# NUC400_v1 register map
File version: 1.0
Registers are 32-bit, read-write, reset 0x0 unless marked. A register's access mark holds for its fields unless they carry their own. Offsets are from the block's base; [hi:lo] are bit positions; {n}, {i} and the like mark numbered series.

## ACMP — ACMP Register Map
Base 0x40045000
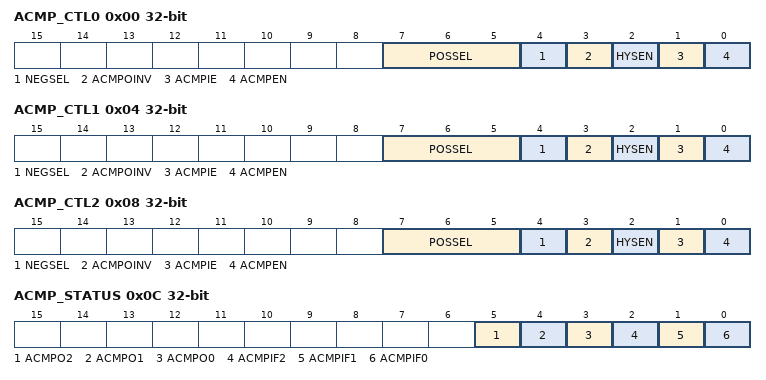
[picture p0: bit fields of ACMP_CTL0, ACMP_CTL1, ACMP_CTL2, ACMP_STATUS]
0x00 ACMP_CTL0 — Analog Comparator 0 Control Register
  [7:5] POSSEL — Comparator 0 Positive Input Selection. The other options are reserved.
    {v}=Input from ACMP0_P{v} (v=0..3); 4=Input from OPA0
  [4] NEGSEL — Comparator 0 Negative Input Selection
    0=The source of comparator 0 negative input is from ACMP0_N pin; 1=The internal comparator reference voltage (Band-gap voltage or CRV) is selected as the source of comparator 0 negative input
  [3] ACMPOINV — Comparator 0 Output Inverse
    0=Comparator 0 output inverse Disabled; 1=Comparator 0 output inverse Enabled
  [2] HYSEN — Comparator 0 Hysteresis Enable Bit
    0=Comparator 0 hysteresis Disabled (Default); 1=Comparator 0 hysteresis Enabled (typical range is 20 mV)
  [1] ACMPIE — Comparator 0 Interrupt Enable Bit
    0=Comparator 0 interrupt Disabled; 1=Comparator 0 interrupt Enabled
  [0] ACMPEN — Comparator 0 Enable Bit. Note: The comparator output needs to wait 2 us stable time after ACMPEN is set.
    0=Comparator 0 Disabled; 1=Comparator 0 Enabled
0x04 ACMP_CTL1 — Analog Comparator 1 Control Register
  [7:5] POSSEL — Comparator 1 Positive Input Selection. The other options are reserved.
    {v}=Input from ACMP1_P{v} (v=0..3); 4=Input from OPA1
  [4] NEGSEL — Comparator 1 Negative Input Selection
    0=The source of comparator 1 negative input is from ACMP1_N pin; 1=The internal comparator reference voltage (Band-gap voltage or CRV) is selected as the source of comparator 1 negative input
  [3] ACMPOINV — Comparator 1 Output Inverse Control
    0=Comparator 1 output inverse Disabled; 1=Comparator 1 output inverse Enabled
  [2] HYSEN — Comparator 1 Hysteresis Enable Bit
    0=Comparator 1 hysteresis Disabled (Default); 1=Comparator 1 hysteresis Enabled (typical range is 20 mV)
  [1] ACMPIE — Comparator 1 Interrupt Enable Bit
    0=Comparator 1 interrupt Disabled; 1=Comparator 1 interrupt Enabled
  [0] ACMPEN — Comparator 1 Enable Bit. The comparator output needs to wait 2 us stable time after ACMPEN is set.
    0=Comparator 1 Disabled; 1=Comparator 1 Enabled
0x08 ACMP_CTL2 — Analog Comparator 2 Control Register
  [7:5] POSSEL — Comparator 2 Positive Input Selection. The other options are reserved.
    {v}=Input from ACMP2_P{v} (v=0..3)
  [4] NEGSEL — Comparator 2 Negative Input Selection
    0=The source of comparator 2 negative input is from ACMP2_N pin; 1=The internal comparator reference voltage (Band-gap voltage or CRV) is selected as the source of comparator 2 negative input
  [3] ACMPOINV — Comparator 2 Output Inverse Control
    0=Comparator 2 output inverse Disabled; 1=Comparator 2 output inverse Enabled
  [2] HYSEN — Comparator 2 Hysteresis Enable Bit
    0=Comparator 2 hysteresis Disabled (Default); 1=Comparator 2 hysteresis Enabled (typical range is 20 mV)
  [1] ACMPIE — Comparator 2 Interrupt Enable Bit
    0=Comparator 2 interrupt Disabled; 1=Comparator 2 interrupt Enabled
  [0] ACMPEN — Comparator 2 Enable Bit. The comparator output needs to wait 2 us stable time after ACMPEN is set.
    0=Comparator 2 Disabled; 1=Comparator 2 Enabled
0x0C ACMP_STATUS — Analog Comparator Status Register
  [5] ACMPO2 — Comparator 2 Output
  [4] ACMPO1 — Comparator 1 Output
  [3] ACMPO0 — Comparator 0 Output
  [2] ACMPIF2 — Comparator 2 Flag. This bit is set by hardware whenever the comparator 2 output changes state. This will cause an interrupt if ACMP_CTL2[1] is set to 1. Write 1 to clear this bit to 0.
  [1] ACMPIF1 — Comparator 1 Flag. This bit is set by hardware whenever the comparator 1 output changes state. This will cause an interrupt if ACMP_CTL1[1] is set to 1. Write 1 to clear this bit to 0.
  [0] ACMPIF0 — Comparator 0 Flag. This bit is set by hardware whenever the comparator 0 output changes state. This will cause an interrupt if ACMP_CTL0[1] is set to 1. Write 1 to clear this bit to 0.
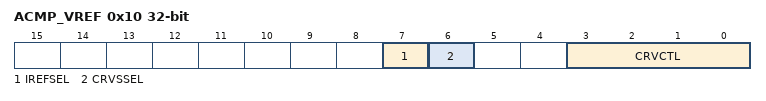
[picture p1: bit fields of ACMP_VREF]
0x10 ACMP_VREF — Analog Comparator Reference Voltage Control Register
  [7] IREFSEL — Internal Reference Selection
    0=Band-gap voltage is selected as internal reference; 1=CRV is selected as internal reference
  [6] CRVSSEL — CRV Source Voltage Selection
    0=AVDD is selected as CRV source voltage; 1=Internal reference voltage is selected as CRV source voltage
  [3:0] CRVCTL — Comparator Reference Voltage Setting
